# EFR32BG22 register map
Vendor: Silicon Labs; Series: EFR32; File version: C
Registers are 32-bit, read-write, reset 0x0 unless marked. A register's access mark holds for its fields unless they carry their own. Offsets are from the block's base; [hi:lo] are bit positions; {n}, {i} and the like mark numbered series; 'fields as' and 'values as' point back to an identical list.

## PDM_S — PDM_S Registers
Base 0x40098000
0x00 IPVERSION ro
0x04 EN
  [0] EN — PDM enable
    0=DISABLE (Disable module); 1=ENABLE (Enable module)
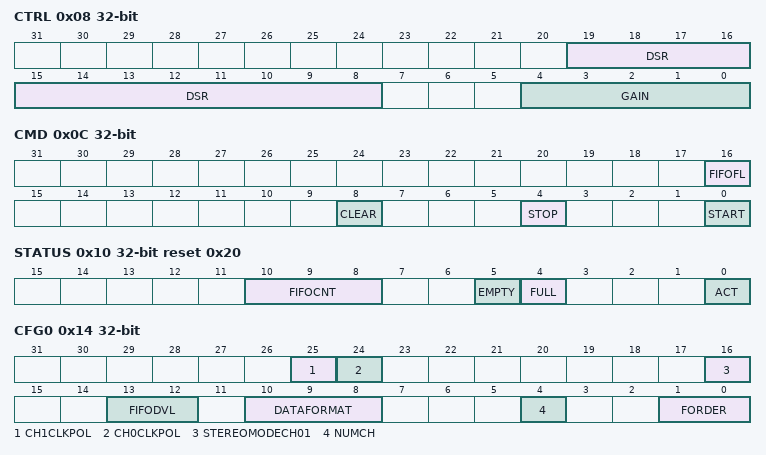
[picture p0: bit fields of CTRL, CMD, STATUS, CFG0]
0x08 CTRL
  [19:8] DSR — Down sampling rate of Decimation filter
  [4:0] GAIN — Selects Gain factor of DCF
0x0C CMD wo
  [16] FIFOFL — FIFO Flush
  [8] CLEAR — Clear DCF
  [4] STOP — Stop DCF
  [0] START — Start DCF
0x10 STATUS ro reset 0x20
  [10:8] FIFOCNT
  [5] EMPTY — FIFO EMPTY Status
  [4] FULL — FIFO FULL Status
  [0] ACT — PDM is active
0x14 CFG0
  [25] CH1CLKPOL — CH1 CLK Polarity
    0=NORMAL (Input data clocked on rising clock edge.); 1=INVERT (Input data clocked on falling clock edge.)
  [24] CH0CLKPOL — CH0 CLK Polarity
    values as CH1CLKPOL
  [16] STEREOMODECH01
    0=DISABLE (No Stereo mode.); 1=CH01ENABLE (CH0 and CH1 in Stereo mode.)
  [13:12] FIFODVL — Data Valid level in FIFO
    0=ONE (Atleast one word.); 1=TWO (Two words.); 2=THREE (Three words.); 3=FOUR (Four words.)
  [10:8] DATAFORMAT — Filter output format
    0=RIGHT16 (Right aligned 16-bit, left bits are sign extended.); 1=DOUBLE16 (Pack two 16-bit samples into one 32-bit word.); 2=RIGHT24 (Right aligned 24bit, left bits are sign extended.); 3=FULL32BIT (32 bit data.); 4=LEFT16 (Left aligned 16-bit, right bits are zeros.); 5=LEFT24 (Left aligned 24-bit, right bits are zeros.); 6=RAW32BIT (RAW 32 bit data from Integrator.)
  [4] NUMCH — Number of Channels
    0=ONE (One channel.); 1=TWO (Two channels.)
  [1:0] FORDER — Filter order
    0=SECOND (Second order filter.); 1=THIRD (Third order filter.); 2=FOURTH (Fourth order filter.); 3=FIFTH (Fifth order filter.)
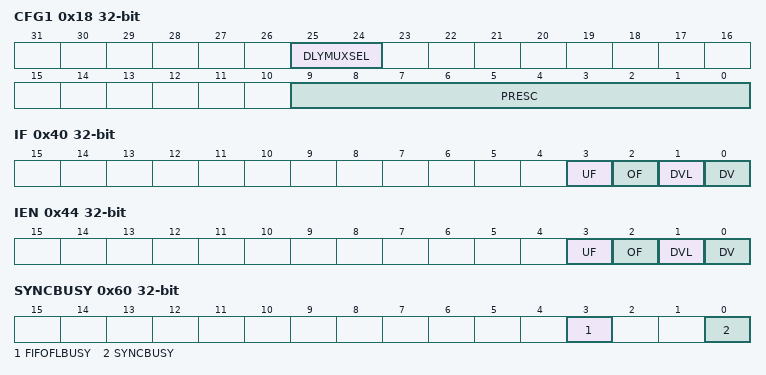
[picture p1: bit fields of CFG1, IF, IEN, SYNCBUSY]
0x18 CFG1
  [25:24] DLYMUXSEL — Data delay buffer mux selection
  [9:0] PRESC — Prescalar Setting for PDM sample
0x20 RXDATA ro
  [31:0] RXDATA — PDM received data
0x40 IF
  [3] UF — FIFO Undeflow Interrupt Flag
  [2] OF — FIFO Overflow Interrupt Flag
  [1] DVL — Data Valid Level Interrupt Flag
  [0] DV — Data Valid Interrupt Flag
0x44 IEN
  [3] UF — FIFO Undeflow Interrupt Enable
  [2] OF — FIFO Overflow Interrupt Enable
  [1] DVL — Data Valid Level Interrupt Enable
  [0] DV — Data Valid Interrupt Enable
0x60 SYNCBUSY ro
  [3] FIFOFLBUSY — FIFO Flush Sync busy
  [0] SYNCBUSY

## SMU_S_CFGNS — SMU_S_CFGNS Registers
Base 0x4400C000
0x04 NSSTATUS ro — Register for status flags.
  [0] SMUNSLOCK — SMUNS Lock Status
    0=UNLOCKED (SMUNSLOCK Unlocked); 1=LOCKED (SMUNSLOCK Locked)
0x08 NSLOCK wo — Register used to lock/unlock access to the register file.
  [23:0] SMUNSLOCKKEY — SMU Non-Secure Lock/Key
    0xACCE55=UNLOCK (Unlocks Registers)
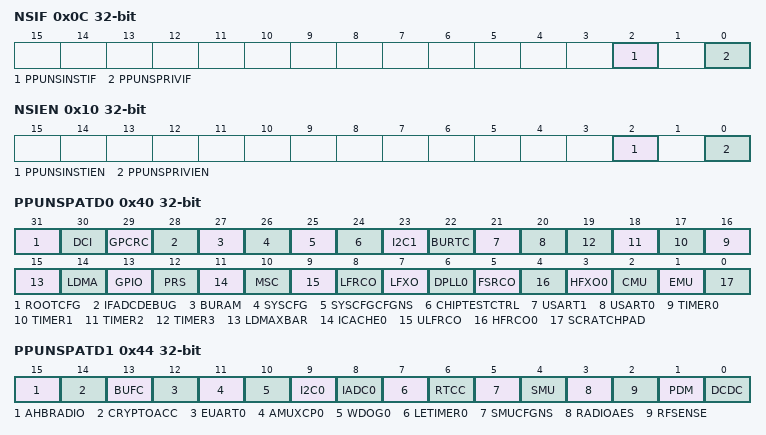
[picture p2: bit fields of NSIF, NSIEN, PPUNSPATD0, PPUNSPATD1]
0x0C NSIF — Register for interrupt status flags.
  [2] PPUNSINSTIF — PPUNS Instruction Interrupt Flag
  [0] PPUNSPRIVIF — PPUNS Privilege Interrupt Flag
0x10 NSIEN — Register used for enabling/disabling interrupts.
  [2] PPUNSINSTIEN — PPUNS Instruction Interrupt Enable
  [0] PPUNSPRIVIEN — PPUNS Privilege Interrupt Enable
0x40 PPUNSPATD0 — Set peripheral bits to 1 to mark as privileged access only.
  [31] ROOTCFG — ROOTCFG Privileged Access
  [30] DCI — DCI Privileged Access
  [29] GPCRC — GPCRC Privileged Access
  [28] IFADCDEBUG — IFADCDEBUG Privileged Access
  [27] BURAM — BURAM Privileged Access
  [26] SYSCFG — SYSCFG Privileged Access
  [25] SYSCFGCFGNS — SYSCFGCFGNS Privileged Access
  [24] CHIPTESTCTRL — CHIPTESTCTRL Privileged Access
  [23] I2C1 — I2C1 Privileged Access
  [22] BURTC — BURTC Privileged Access
  [21] USART1 — USART1 Privileged Access
  [20] USART0 — USART0 Privileged Access
  [n+16] TIMER{n} (n=0..3) — TIMER{n} Privileged Access
  [15] LDMAXBAR — LDMAXBAR Privileged Access
  [14] LDMA — LDMA Privileged Access
  [13] GPIO — GPIO Privileged Access
  [12] PRS — PRS Privileged Access
  [11] ICACHE0 — ICACHE0 Privileged Access
  [10] MSC — MSC Privileged Access
  [9] ULFRCO — ULFRCO Privileged Access
  [8] LFRCO — LFRCO Privileged Access
  [7] LFXO — LFXO Privileged Access
  [6] DPLL0 — DPLL0 Privileged Access
  [5] FSRCO — FSRCO Privileged Access
  [4] HFRCO0 — HFRCO0 Privileged Access
  [3] HFXO0 — HFXO0 Privileged Access
  [2] CMU — CMU Privileged Access
  [1] EMU — EMU Privileged Access
  [0] SCRATCHPAD — SCRATCHPAD Privileged Access
0x44 PPUNSPATD1 — Set peripheral bits to 1 to mark as privileged access only.
  [15] AHBRADIO — AHBRADIO Privileged Access
  [14] CRYPTOACC — CRYPTOACC Privileged Access
  [13] BUFC — BUFC Privileged Access
  [12] EUART0 — EUART0 Privileged Access
  [11] AMUXCP0 — AMUXCP0 Privileged Access
  [10] WDOG0 — WDOG0 Privileged Access
  [9] I2C0 — I2C0 Privileged Access
  [8] IADC0 — IADC0 Privileged Access
  [7] LETIMER0 — LETIMER0 Privileged Access
  [6] RTCC — RTCC Privileged Access
  [5] SMUCFGNS — SMUCFGNS Privileged Access
  [4] SMU — SMU Privileged Access
  [3] RADIOAES — RADIOAES Privileged Access
  [2] RFSENSE — RFSENSE Privileged Access
  [1] PDM — PDM Privileged Access
  [0] DCDC — DCDC Privileged Access
0x140 PPUNSFS ro — Read this register to query the fault status.
  [7:0] PPUFSPERIPHID — Peripheral ID
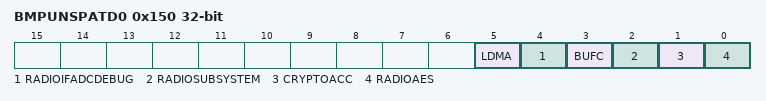
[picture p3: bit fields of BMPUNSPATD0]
0x150 BMPUNSPATD0 — Write to set BMPU priveledged attributes.
  [5] LDMA — MCU LDMA privileged mode
  [4] RADIOIFADCDEBUG — RADIO IFADC debug privileged mode
  [3] BUFC — RADIO BUFFER controller privileged mode
  [2] RADIOSUBSYSTEM — RADIO subsystem masters privileged mode
  [1] CRYPTOACC — CRYPTOACC DMA privileged mode
  [0] RADIOAES — RADIO AES DMA privileged mode
